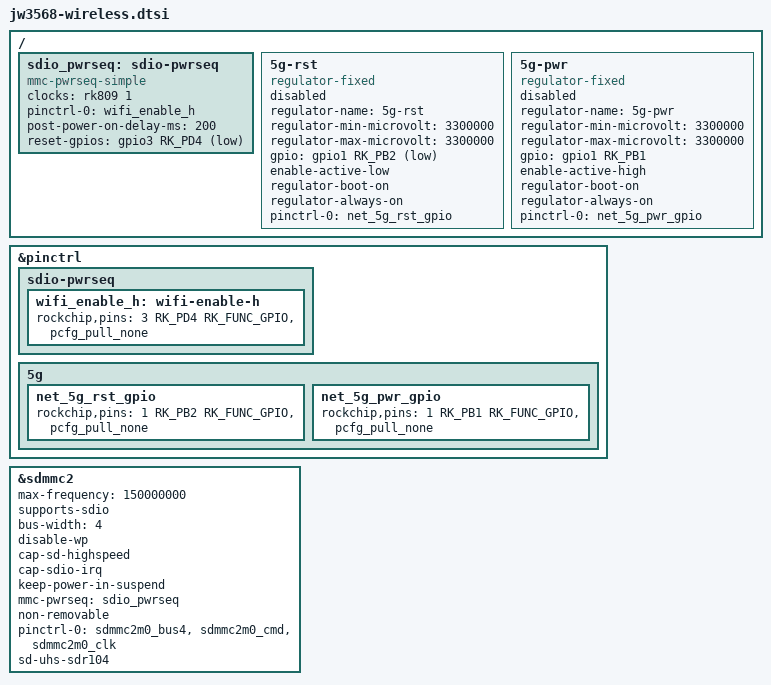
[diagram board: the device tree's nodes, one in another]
/ {
	sdio_pwrseq: sdio-pwrseq {
		compatible = "mmc-pwrseq-simple";
		clocks = <&rk809 1>;
		clock-names = "ext_clock";
		pinctrl-names = "default";
		pinctrl-0 = <&wifi_enable_h>;

		/*
		 * On the module itself this is one of these (depending
		 * on the actual card populated):
		 * - SDIO_RESET_L_WL_REG_ON
		 * - PDN (power down when low)
		 */
		post-power-on-delay-ms = <200>;
		reset-gpios = <&gpio3 RK_PD4 GPIO_ACTIVE_LOW>;
	};

	5g-rst {
        compatible = "regulator-fixed";
        regulator-name = "5g-rst";
        regulator-min-microvolt = <3300000>;
        regulator-max-microvolt = <3300000>;
        gpio = <&gpio1 RK_PB2 GPIO_ACTIVE_LOW>;
        enable-active-low;
        regulator-boot-on;
        regulator-always-on;
		pinctrl-names = "default";
		pinctrl-0 = <&net_5g_rst_gpio>;
        status = "disabled";
    };

    5g-pwr {
        compatible = "regulator-fixed";
        regulator-name = "5g-pwr";
        regulator-min-microvolt = <3300000>;
        regulator-max-microvolt = <3300000>;
        gpio = <&gpio1 RK_PB1 GPIO_ACTIVE_HIGH>;
        enable-active-high;
        regulator-boot-on;
        regulator-always-on;
		pinctrl-names = "default";
		pinctrl-0 = <&net_5g_pwr_gpio>;
        status = "disabled";
    };
};

&pinctrl {
	sdio-pwrseq {
		wifi_enable_h: wifi-enable-h {
			rockchip,pins = <3 RK_PD4 RK_FUNC_GPIO &pcfg_pull_none>;
		};
	};

	5g {
		net_5g_rst_gpio: net_5g_rst_gpio {
			rockchip,pins = <1 RK_PB2 RK_FUNC_GPIO &pcfg_pull_none>;
		};

		net_5g_pwr_gpio: net_5g_pwr_gpio {
			rockchip,pins = <1 RK_PB1 RK_FUNC_GPIO &pcfg_pull_none>;
		};
	};
};

&sdmmc2 {
	max-frequency = <150000000>;
	supports-sdio;
	bus-width = <4>;
	disable-wp;
	cap-sd-highspeed;
	cap-sdio-irq;
	keep-power-in-suspend;
	mmc-pwrseq = <&sdio_pwrseq>;
	non-removable;
	pinctrl-names = "default";
	pinctrl-0 = <&sdmmc2m0_bus4 &sdmmc2m0_cmd &sdmmc2m0_clk>;
	sd-uhs-sdr104;
	status = "okay";
};
